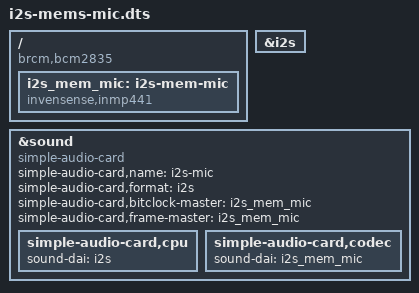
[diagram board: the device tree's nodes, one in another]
/dts-v1/;
/plugin/;

/ {
    compatible = "brcm,bcm2835";

    fragment@0 {
        target = <&i2s>;
        __overlay__ {
            status = "okay";
        };
    };

    fragment@1 {
        target-path = "/";
        __overlay__ {
            i2s_mem_mic: i2s-mem-mic {
                #sound-dai-cells = <0>;
                compatible = "invensense,inmp441";
                status = "okay";
            };
        };
    };

    fragment@2 {
        target = <&sound>;
        __overlay__ {
            compatible = "simple-audio-card";
            simple-audio-card,name = "i2s-mic";
            simple-audio-card,format = "i2s";
            simple-audio-card,bitclock-master = <&i2s_mem_mic>;
            simple-audio-card,frame-master = <&i2s_mem_mic>;
            simple-audio-card,cpu {
                sound-dai = <&i2s>;
            };
            simple-audio-card,codec {
                sound-dai = <&i2s_mem_mic>;
            };
        };
    };
};
